# AST1080 register map
File version: 1.0
CPU: CM4 r0p1, little endian, MPU, FPU, 4 interrupt priority bits, 256 interrupts
Registers are 32-bit, read-write, reset 0x0 unless marked. A register's access mark holds for its fields unless they carry their own. Offsets are from the block's base; [hi:lo] are bit positions; {n}, {i} and the like mark numbered series.

## i2cbuff
Base 0x74C0F1A0
Same registers: i2cbuff{n} {0x74C0F1A0+0x100*n} (n=1..13)
{0x0+4i} BUFF[{i}] (i=0..7) — I2C Buffer Mode Buff
  [31:0] Data

## timer
Base 0x74C3A000
Same registers: timer1 0x74C3A040, timer2 0x74C3A080, timer3 0x74C3A0C0, timer4 0x74C3A100, timer5 0x74C3A140, timer6 0x74C3A180, timer7 0x74C3A1C0
0x00 TIMER000 — Counter Status Register
  [31:0] CounterSts — Counter status
0x04 TIMER004 — Counter Reload Value Register
  [31:0] CounterReloadValueReg — Counter reload value register
0x08 TIMER008 — Counter First Matching Register
  [31:0] FirstSetMatchReg — First set match register
0x0C TIMER00C — Counter Second Matching Register
  [31:0] SecondaryMatchReg — Secondary match register
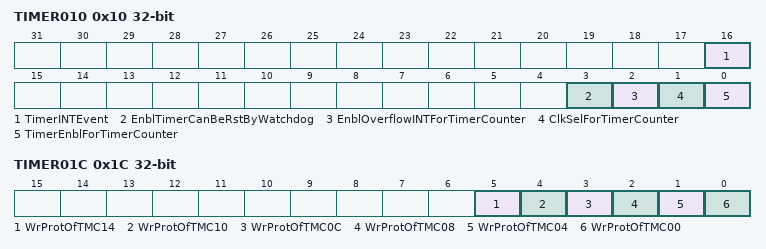
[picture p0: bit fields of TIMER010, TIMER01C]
0x10 TIMER010 — Counter Control and Interrupt Status Register
  [16] TimerINTEvent — Timer Interrupt Event
  [3] EnblTimerCanBeRstByWatchdog — Enable Timer can be reset by watchdog
  [2] EnblOverflowINTForTimerCounter — Enable Overflow Interrupt for Timer/Counter
    0=Disable; 1=Enable_When_Timer_Overflow_Count_To_0_Occurred_Interrupt_Will_Be_Generated
  [1] ClkSelForTimerCounter — Clock selection for Timer/Counter
    0=APB_Clock_PCLK; 1=1_MHz_Clock
  [0] TimerEnblForTimerCounter — Timer enable for Timer/Counter
    0=Disable; 1=Enable
0x1C TIMER01C — Conter Write Protection Register
  [5] WrProtOfTMC14 — Write Protection of TMC14
  [4] WrProtOfTMC10 — Write Protection of TMC10
  [3] WrProtOfTMC0C — Write Protection of TMC0C
  [2] WrProtOfTMC08 — Write Protection of TMC08
  [1] WrProtOfTMC04 — Write Protection of TMC04
  [0] WrProtOfTMC00 — Write Protection of TMC00

## sprot
Base 0x74000800
Same registers: sprot1 0x74010800, sprot2 0x74020800
0x00 SPROT000 reset 0x2 — SPROT\_CFG
  [7:0] UNIT ro
0x0C SPROT00C — SPROT\_WLOCK
  [3:0] WLOCK
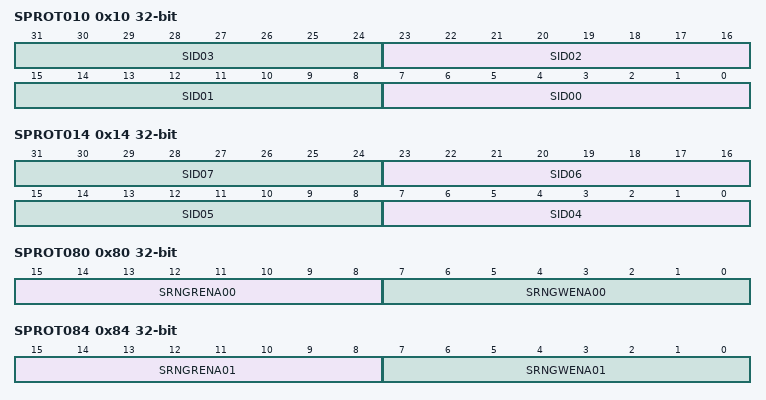
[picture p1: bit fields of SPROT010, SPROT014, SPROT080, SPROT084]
0x10 SPROT010 — SPROT\_SIDG0
  [8n+7:8n] SID{n:02} (n=0..3)
0x14 SPROT014 — SPROT\_SIDG1
  [8n-25:8n-32] SID{n:02} (n=4..7)
0x80 SPROT080 — SPROT\_CTL00
  [15:8] SRNGRENA00, [7:0] SRNGWENA00
0x84 SPROT084 — SPROT\_CTL01
  [15:8] SRNGRENA01, [7:0] SRNGWENA01
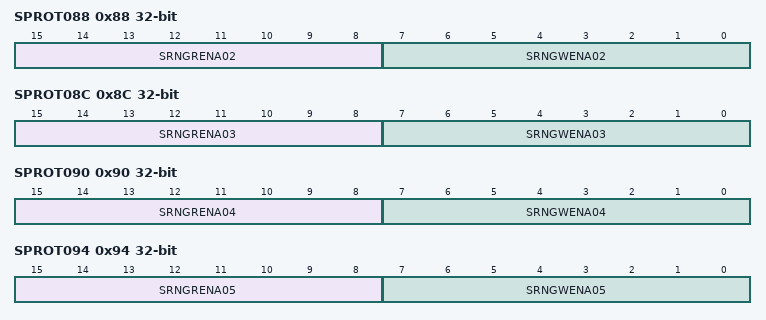
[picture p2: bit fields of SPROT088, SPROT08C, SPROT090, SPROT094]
0x88 SPROT088 — SPROT\_CTL02
  [15:8] SRNGRENA02, [7:0] SRNGWENA02
0x8C SPROT08C — SPROT\_CTL03
  [15:8] SRNGRENA03, [7:0] SRNGWENA03
0x90 SPROT090 — SPROT\_CTL04
  [15:8] SRNGRENA04, [7:0] SRNGWENA04
0x94 SPROT094 — SPROT\_CTL05
  [15:8] SRNGRENA05, [7:0] SRNGWENA05
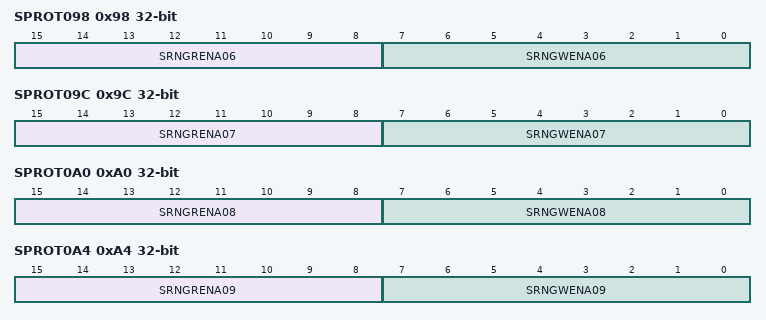
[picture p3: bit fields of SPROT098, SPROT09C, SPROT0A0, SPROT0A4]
0x98 SPROT098 — SPROT\_CTL06
  [15:8] SRNGRENA06, [7:0] SRNGWENA06
0x9C SPROT09C — SPROT\_CTL07
  [15:8] SRNGRENA07, [7:0] SRNGWENA07
0xA0 SPROT0A0 — SPROT\_CTL08
  [15:8] SRNGRENA08, [7:0] SRNGWENA08
0xA4 SPROT0A4 — SPROT\_CTL09
  [15:8] SRNGRENA09, [7:0] SRNGWENA09
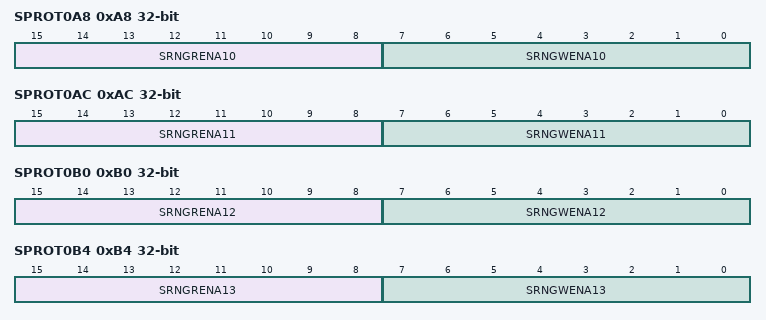
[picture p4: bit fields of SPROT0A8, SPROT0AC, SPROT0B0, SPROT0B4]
0xA8 SPROT0A8 — SPROT\_CTL10
  [15:8] SRNGRENA10, [7:0] SRNGWENA10
0xAC SPROT0AC — SPROT\_CTL11
  [15:8] SRNGRENA11, [7:0] SRNGWENA11
0xB0 SPROT0B0 — SPROT\_CTL12
  [15:8] SRNGRENA12, [7:0] SRNGWENA12
0xB4 SPROT0B4 — SPROT\_CTL13
  [15:8] SRNGRENA13, [7:0] SRNGWENA13
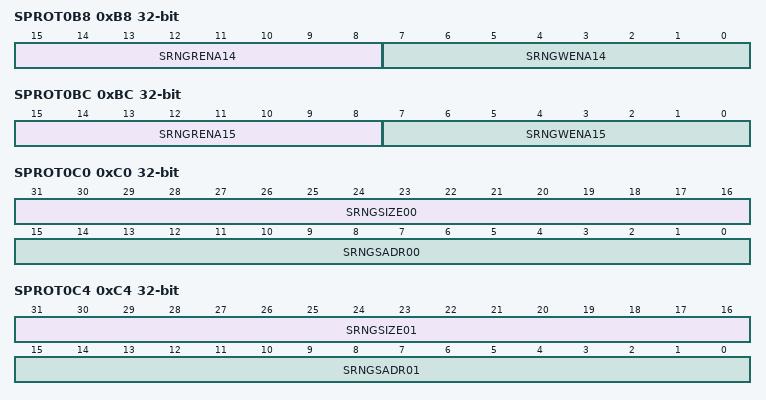
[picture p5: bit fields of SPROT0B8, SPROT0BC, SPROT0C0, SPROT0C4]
0xB8 SPROT0B8 — SPROT\_CTL14
  [15:8] SRNGRENA14, [7:0] SRNGWENA14
0xBC SPROT0BC — SPROT\_CTL15
  [15:8] SRNGRENA15, [7:0] SRNGWENA15
0xC0 SPROT0C0 — SPROT\_ADR00
  [31:16] SRNGSIZE00, [15:0] SRNGSADR00
0xC4 SPROT0C4 — SPROT\_ADR01
  [31:16] SRNGSIZE01, [15:0] SRNGSADR01
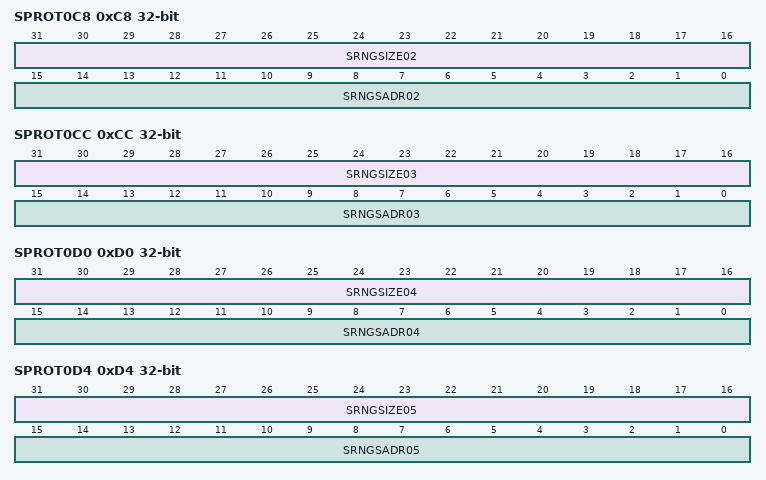
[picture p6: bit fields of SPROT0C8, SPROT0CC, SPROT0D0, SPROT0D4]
0xC8 SPROT0C8 — SPROT\_ADR02
  [31:16] SRNGSIZE02, [15:0] SRNGSADR02
0xCC SPROT0CC — SPROT\_ADR03
  [31:16] SRNGSIZE03, [15:0] SRNGSADR03
0xD0 SPROT0D0 — SPROT\_ADR04
  [31:16] SRNGSIZE04, [15:0] SRNGSADR04
0xD4 SPROT0D4 — SPROT\_ADR05
  [31:16] SRNGSIZE05, [15:0] SRNGSADR05
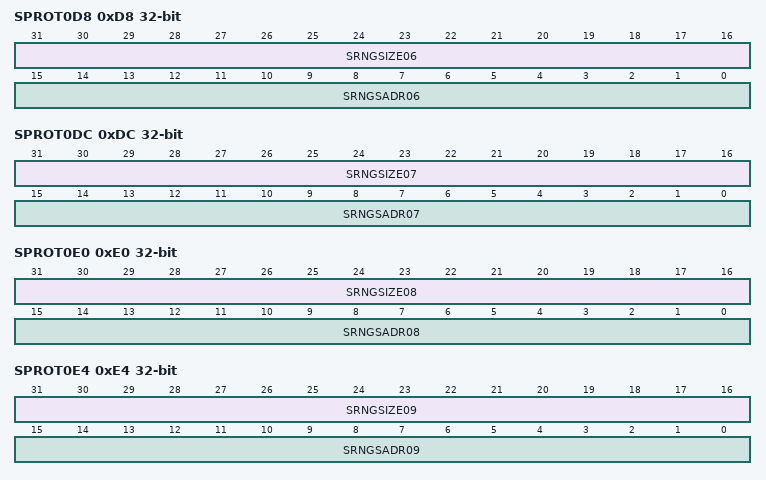
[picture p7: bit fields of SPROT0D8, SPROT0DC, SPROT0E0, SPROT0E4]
0xD8 SPROT0D8 — SPROT\_ADR06
  [31:16] SRNGSIZE06, [15:0] SRNGSADR06
0xDC SPROT0DC — SPROT\_ADR07
  [31:16] SRNGSIZE07, [15:0] SRNGSADR07
0xE0 SPROT0E0 — SPROT\_ADR08
  [31:16] SRNGSIZE08, [15:0] SRNGSADR08
0xE4 SPROT0E4 — SPROT\_ADR09
  [31:16] SRNGSIZE09, [15:0] SRNGSADR09
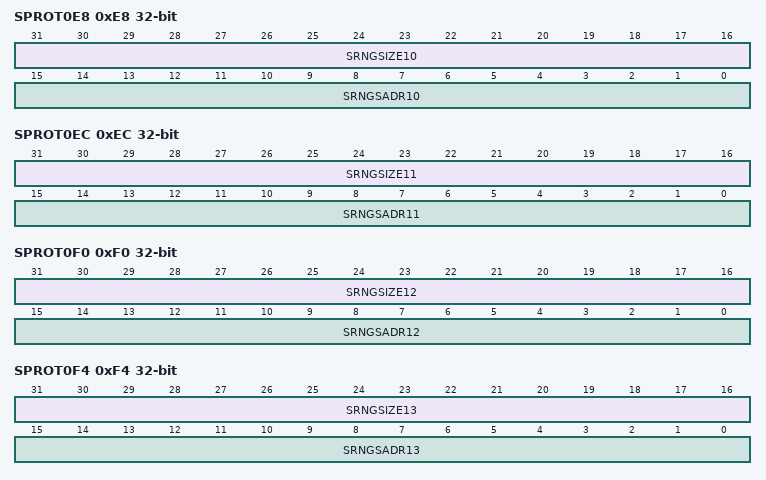
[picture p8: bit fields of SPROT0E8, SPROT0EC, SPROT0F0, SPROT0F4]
0xE8 SPROT0E8 — SPROT\_ADR10
  [31:16] SRNGSIZE10, [15:0] SRNGSADR10
0xEC SPROT0EC — SPROT\_ADR11
  [31:16] SRNGSIZE11, [15:0] SRNGSADR11
0xF0 SPROT0F0 — SPROT\_ADR12
  [31:16] SRNGSIZE12, [15:0] SRNGSADR12
0xF4 SPROT0F4 — SPROT\_ADR13
  [31:16] SRNGSIZE13, [15:0] SRNGSADR13
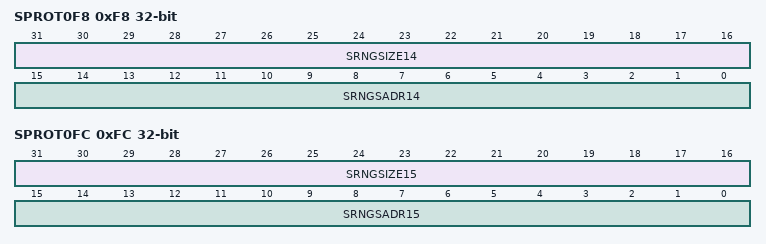
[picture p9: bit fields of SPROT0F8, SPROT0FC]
0xF8 SPROT0F8 — SPROT\_ADR14
  [31:16] SRNGSIZE14, [15:0] SRNGSADR14
0xFC SPROT0FC — SPROT\_ADR15
  [31:16] SRNGSIZE15, [15:0] SRNGSADR15
